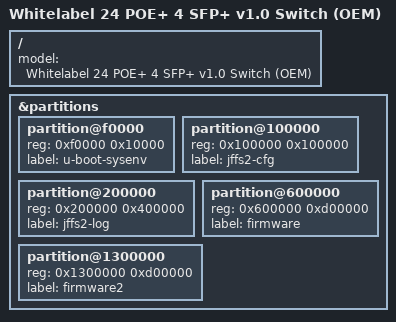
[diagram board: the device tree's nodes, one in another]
// SPDX-License-Identifier: (GPL-2.0-or-later OR MIT)
/dts-v1/;

#include "rtl9301_whitelabel_ws-sw-24p-4s_r1_v1.0.dts"

/ {
	model = "Whitelabel 24 POE+ 4 SFP+ v1.0 Switch (OEM)";
};

&partitions {
	/delete-node/ partition@f0000;
	partition@f0000 {
		reg = <0xf0000 0x10000>;
		label = "u-boot-sysenv";
	};

	partition@100000 {
		reg = <0x100000 0x100000>;
		label = "jffs2-cfg";
	};

	partition@200000 {
		reg = <0x200000 0x400000>;
		label = "jffs2-log";
	};

	partition@600000 {
		reg = <0x600000 0xd00000>;
		label = "firmware";
	};

	partition@1300000 {
		reg = <0x1300000 0xd00000>;
		label = "firmware2";
	};
};
